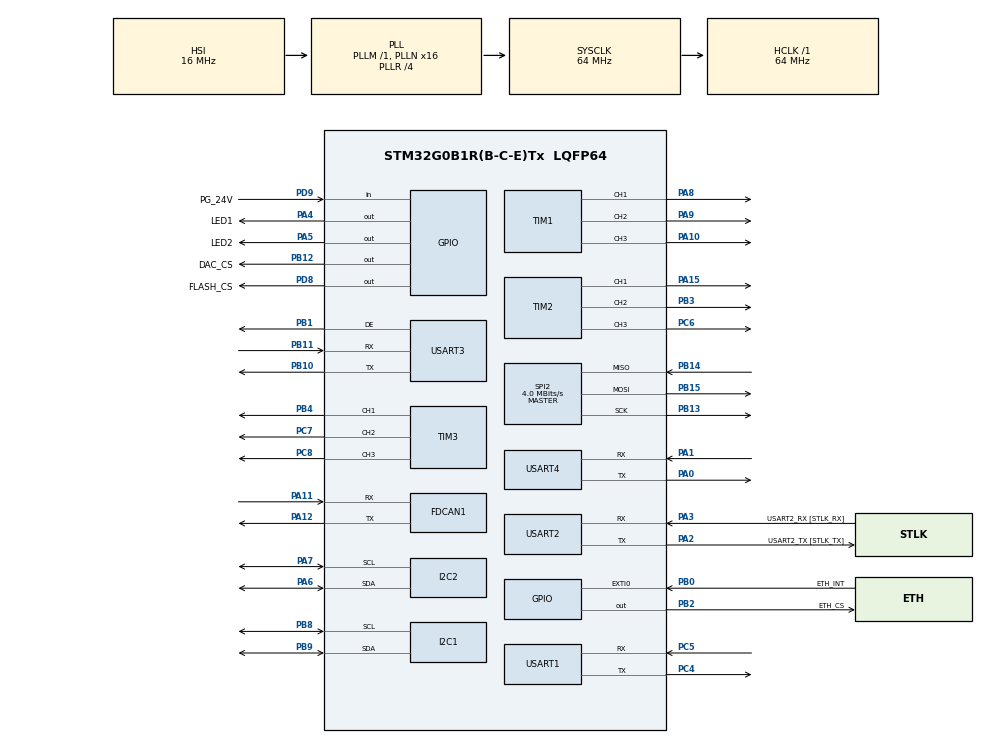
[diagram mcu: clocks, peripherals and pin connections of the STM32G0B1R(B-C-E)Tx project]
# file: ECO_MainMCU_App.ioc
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ADC1.AWD1HighThreshold=2500
ADC1.AWD1ITMode=ENABLE
ADC1.AWD1LowThreshold=2000
ADC1.Channel-0\#ChannelRegularConversion=ADC_CHANNEL_VREFINT
ADC1.Channel-1\#ChannelRegularConversion=ADC_CHANNEL_VBAT
ADC1.Channel-2\#ChannelRegularConversion=ADC_CHANNEL_TEMPSENSOR
ADC1.ClockPrescaler=ADC_CLOCK_SYNC_PCLK_DIV2
ADC1.DMAContinuousRequests=ENABLE
ADC1.DiscontinuousConvMode=DISABLE
ADC1.EOCSelection=ADC_EOC_SEQ_CONV
ADC1.EnableAnalogWatchDog1=true
ADC1.NbrOfConversion=3
ADC1.NbrOfConversionFlag=1
ADC1.OversamplingMode=ENABLE
ADC1.Rank-0\#ChannelRegularConversion=1
ADC1.Rank-1\#ChannelRegularConversion=2
ADC1.Rank-2\#ChannelRegularConversion=3
ADC1.Ratio=ADC_OVERSAMPLING_RATIO_16
ADC1.RightBitShift=ADC_RIGHTBITSHIFT_2
ADC1.SamplingTime-0\#ChannelRegularConversion=ADC_SAMPLINGTIME_COMMON_1
ADC1.SamplingTime-1\#ChannelRegularConversion=ADC_SAMPLINGTIME_COMMON_1
ADC1.SamplingTime-2\#ChannelRegularConversion=ADC_SAMPLINGTIME_COMMON_1
ADC1.SamplingTimeCommon1=ADC_SAMPLETIME_79CYCLES_5
ADC1.SamplingTimeCommon2=ADC_SAMPLETIME_79CYCLES_5
ADC1.SelectedChannel=ADC_CHANNEL_TEMPSENSOR|ADC_CHANNEL_VREFINT|ADC_CHANNEL_VBAT
ADC1.TriggerFrequencyMode=ADC_TRIGGER_FREQ_LOW
ADC1.TriggeredMode=ADC_TRIGGEREDMODE_SINGLE_TRIGGER
ADC1.WatchdogChannel=ADC_CHANNEL_VREFINT
ADC1.master=1
CRC.CRCLength=CRC_POLYLENGTH_16B
CRC.DefaultInitValueUse=DEFAULT_INIT_VALUE_DISABLE
CRC.DefaultPolynomialUse=DEFAULT_POLYNOMIAL_DISABLE
CRC.InputDataInversionMode=CRC_INPUTDATA_INVERSION_BYTE
CRC.OutputDataInversionMode=CRC_OUTPUTDATA_INVERSION_ENABLE
Dma.ADC1.0.Direction=DMA_PERIPH_TO_MEMORY
Dma.ADC1.0.EventEnable=DISABLE
Dma.ADC1.0.Instance=DMA1_Channel1
Dma.ADC1.0.MemDataAlignment=DMA_MDATAALIGN_HALFWORD
Dma.ADC1.0.MemInc=DMA_MINC_ENABLE
Dma.ADC1.0.Mode=DMA_CIRCULAR
Dma.ADC1.0.PeriphDataAlignment=DMA_PDATAALIGN_HALFWORD
Dma.ADC1.0.PeriphInc=DMA_PINC_DISABLE
Dma.ADC1.0.Polarity=HAL_DMAMUX_REQ_GEN_RISING
Dma.ADC1.0.Priority=DMA_PRIORITY_LOW
Dma.ADC1.0.RequestNumber=1
Dma.ADC1.0.SignalID=NONE
Dma.ADC1.0.SyncEnable=DISABLE
Dma.ADC1.0.SyncPolarity=HAL_DMAMUX_SYNC_NO_EVENT
Dma.ADC1.0.SyncRequestNumber=1
Dma.ADC1.0.SyncSignalID=NONE
Dma.Request0=ADC1
Dma.Request1=USART1_RX
Dma.Request2=USART1_TX
Dma.Request3=USART3_RX
Dma.Request4=USART4_RX
Dma.Request5=USART4_TX
Dma.USART1_RX.1.Direction=DMA_PERIPH_TO_MEMORY
Dma.USART1_RX.1.EventEnable=DISABLE
Dma.USART1_RX.1.Instance=DMA2_Channel1
Dma.USART1_RX.1.MemDataAlignment=DMA_MDATAALIGN_BYTE
Dma.USART1_RX.1.MemInc=DMA_MINC_ENABLE
Dma.USART1_RX.1.Mode=DMA_NORMAL
Dma.USART1_RX.1.PeriphDataAlignment=DMA_PDATAALIGN_BYTE
Dma.USART1_RX.1.PeriphInc=DMA_PINC_DISABLE
Dma.USART1_RX.1.Polarity=HAL_DMAMUX_REQ_GEN_RISING
Dma.USART1_RX.1.Priority=DMA_PRIORITY_LOW
Dma.USART1_RX.1.RequestNumber=1
Dma.USART1_RX.1.SignalID=NONE
Dma.USART1_RX.1.SyncEnable=DISABLE
Dma.USART1_RX.1.SyncPolarity=HAL_DMAMUX_SYNC_NO_EVENT
Dma.USART1_RX.1.SyncRequestNumber=1
Dma.USART1_RX.1.SyncSignalID=NONE
Dma.USART1_TX.2.Direction=DMA_MEMORY_TO_PERIPH
Dma.USART1_TX.2.EventEnable=DISABLE
Dma.USART1_TX.2.Instance=DMA2_Channel2
Dma.USART1_TX.2.MemDataAlignment=DMA_MDATAALIGN_BYTE
Dma.USART1_TX.2.MemInc=DMA_MINC_ENABLE
Dma.USART1_TX.2.Mode=DMA_NORMAL
Dma.USART1_TX.2.PeriphDataAlignment=DMA_PDATAALIGN_BYTE
Dma.USART1_TX.2.PeriphInc=DMA_PINC_DISABLE
Dma.USART1_TX.2.Polarity=HAL_DMAMUX_REQ_GEN_RISING
Dma.USART1_TX.2.Priority=DMA_PRIORITY_LOW
Dma.USART1_TX.2.RequestNumber=1
Dma.USART1_TX.2.SignalID=NONE
Dma.USART1_TX.2.SyncEnable=DISABLE
Dma.USART1_TX.2.SyncPolarity=HAL_DMAMUX_SYNC_NO_EVENT
Dma.USART1_TX.2.SyncRequestNumber=1
Dma.USART1_TX.2.SyncSignalID=NONE
Dma.USART3_RX.3.Direction=DMA_PERIPH_TO_MEMORY
Dma.USART3_RX.3.EventEnable=DISABLE
Dma.USART3_RX.3.Instance=DMA2_Channel3
Dma.USART3_RX.3.MemDataAlignment=DMA_MDATAALIGN_BYTE
Dma.USART3_RX.3.MemInc=DMA_MINC_ENABLE
Dma.USART3_RX.3.Mode=DMA_NORMAL
Dma.USART3_RX.3.PeriphDataAlignment=DMA_PDATAALIGN_BYTE
Dma.USART3_RX.3.PeriphInc=DMA_PINC_DISABLE
Dma.USART3_RX.3.Polarity=HAL_DMAMUX_REQ_GEN_RISING
Dma.USART3_RX.3.Priority=DMA_PRIORITY_LOW
Dma.USART3_RX.3.RequestNumber=1
Dma.USART3_RX.3.SignalID=NONE
Dma.USART3_RX.3.SyncEnable=DISABLE
Dma.USART3_RX.3.SyncPolarity=HAL_DMAMUX_SYNC_NO_EVENT
Dma.USART3_RX.3.SyncRequestNumber=1
Dma.USART3_RX.3.SyncSignalID=NONE
Dma.USART4_RX.4.Direction=DMA_PERIPH_TO_MEMORY
Dma.USART4_RX.4.EventEnable=DISABLE
Dma.USART4_RX.4.Instance=DMA2_Channel4
Dma.USART4_RX.4.MemDataAlignment=DMA_MDATAALIGN_BYTE
Dma.USART4_RX.4.MemInc=DMA_MINC_ENABLE
Dma.USART4_RX.4.Mode=DMA_NORMAL
Dma.USART4_RX.4.PeriphDataAlignment=DMA_PDATAALIGN_BYTE
Dma.USART4_RX.4.PeriphInc=DMA_PINC_DISABLE
Dma.USART4_RX.4.Polarity=HAL_DMAMUX_REQ_GEN_RISING
Dma.USART4_RX.4.Priority=DMA_PRIORITY_LOW
Dma.USART4_RX.4.RequestNumber=1
Dma.USART4_RX.4.SignalID=NONE
Dma.USART4_RX.4.SyncEnable=DISABLE
Dma.USART4_RX.4.SyncPolarity=HAL_DMAMUX_SYNC_NO_EVENT
Dma.USART4_RX.4.SyncRequestNumber=1
Dma.USART4_RX.4.SyncSignalID=NONE
Dma.USART4_TX.5.Direction=DMA_MEMORY_TO_PERIPH
Dma.USART4_TX.5.EventEnable=DISABLE
Dma.USART4_TX.5.Instance=DMA2_Channel5
Dma.USART4_TX.5.MemDataAlignment=DMA_MDATAALIGN_BYTE
Dma.USART4_TX.5.MemInc=DMA_MINC_ENABLE
Dma.USART4_TX.5.Mode=DMA_NORMAL
Dma.USART4_TX.5.PeriphDataAlignment=DMA_PDATAALIGN_BYTE
Dma.USART4_TX.5.PeriphInc=DMA_PINC_DISABLE
Dma.USART4_TX.5.Polarity=HAL_DMAMUX_REQ_GEN_RISING
Dma.USART4_TX.5.Priority=DMA_PRIORITY_LOW
Dma.USART4_TX.5.RequestNumber=1
Dma.USART4_TX.5.SignalID=NONE
Dma.USART4_TX.5.SyncEnable=DISABLE
Dma.USART4_TX.5.SyncPolarity=HAL_DMAMUX_SYNC_NO_EVENT
Dma.USART4_TX.5.SyncRequestNumber=1
Dma.USART4_TX.5.SyncSignalID=NONE
FDCAN1.CalculateBaudRateNominal=800000
FDCAN1.CalculateTimeBitNominal=1250
FDCAN1.CalculateTimeQuantumNominal=250.0
I2C1.Timing=0x10707DBC
I2C2.Timing=0x10707DBC
Mcu.Family=STM32G0
Mcu.Name=STM32G0B1R(B-C-E)Tx
Mcu.Package=LQFP64
NVIC.DMA1_Ch4_7_DMA2_Ch1_5_DMAMUX1_OVR_IRQn=true\:0\:0\:false\:false\:true\:false\:true\:true
NVIC.DMA1_Channel1_IRQn=true\:0\:0\:false\:false\:true\:false\:true\:true
NVIC.EXTI0_1_IRQn=true\:3\:0\:true\:false\:true\:true\:true\:true
NVIC.TIM17_FDCAN_IT1_IRQn=true\:3\:0\:false\:false\:true\:false\:true\:true
NVIC.TimeBase=TIM17_FDCAN_IT1_IRQn
NVIC.TimeBaseIP=TIM17
NVIC.USART1_IRQn=true\:3\:0\:true\:false\:true\:true\:true\:true
NVIC.USART2_LPUART2_IRQn=true\:3\:0\:true\:false\:true\:true\:true\:true
NVIC.USART3_4_5_6_LPUART1_IRQn=true\:3\:0\:true\:false\:true\:true\:true\:true
PA0.Mode=Asynchronous
PA0.Signal=USART4_TX
PA1.Mode=Asynchronous
PA1.Signal=USART4_RX
PA10.Signal=S_TIM1_CH3
PA11\ [PA9].Mode=FDCAN_Activate
PA11\ [PA9].Signal=FDCAN1_RX
PA12\ [PA10].Mode=FDCAN_Activate
PA12\ [PA10].Signal=FDCAN1_TX
PA13.GPIO_Label=TMS
PA13.Mode=Serial_Wire
PA13.Signal=SYS_SWDIO
PA14-BOOT0.GPIO_Label=TCK
PA14-BOOT0.Mode=Serial_Wire
PA14-BOOT0.Signal=SYS_SWCLK
PA15.Signal=S_TIM2_CH1_ETR
PA2.GPIO_Label=USART2_TX [STLK_TX]
PA2.Mode=Asynchronous
PA2.Signal=USART2_TX
PA3.GPIO_Label=USART2_RX [STLK_RX]
PA3.Mode=Asynchronous
PA3.Signal=USART2_RX
PA4.GPIO_Label=LED1
PA4.Signal=GPIO_Output
PA5.GPIO_Label=LED2
PA5.GPIO_Speed=GPIO_SPEED_FREQ_HIGH
PA5.Signal=GPIO_Output
PA6.Mode=I2C
PA6.Signal=I2C2_SDA
PA7.Mode=I2C
PA7.Signal=I2C2_SCL
PA8.Signal=S_TIM1_CH1
PA9.Signal=S_TIM1_CH2
PB0.GPIO_Label=ETH_INT
PB0.GPIO_ModeDefaultEXTI=GPIO_MODE_IT_FALLING
PB0.Signal=GPXTI0
PB1.Mode=Hardware Flow Control (RS485)
PB1.Signal=USART3_DE
PB10.Mode=Asynchronous
PB10.Signal=USART3_TX
PB11.Mode=Asynchronous
PB11.Signal=USART3_RX
PB12.GPIO_Label=DAC_CS
PB12.Signal=GPIO_Output
PB13.Mode=Full_Duplex_Master
PB13.Signal=SPI2_SCK
PB14.Mode=Full_Duplex_Master
PB14.Signal=SPI2_MISO
PB15.Mode=Full_Duplex_Master
PB15.Signal=SPI2_MOSI
PB2.GPIO_Label=ETH_CS
PB2.Signal=GPIO_Output
PB3.Signal=S_TIM2_CH2
PB4.Signal=S_TIM3_CH1
PB8.Mode=I2C
PB8.Signal=I2C1_SCL
PB9.Mode=I2C
PB9.Signal=I2C1_SDA
PC13.Mode=SYS_WakeUp1
PC13.Signal=SYS_WKUP2
PC14-OSC32_IN\ (PC14).Mode=LSE-External-Oscillator
PC14-OSC32_IN\ (PC14).Signal=RCC_OSC32_IN
PC15-OSC32_OUT\ (PC15).Mode=LSE-External-Oscillator
PC15-OSC32_OUT\ (PC15).Signal=RCC_OSC32_OUT
PC4.GPIO_PuPd=GPIO_NOPULL
PC4.Mode=Asynchronous
PC4.Signal=USART1_TX
PC5.GPIO_PuPd=GPIO_NOPULL
PC5.Mode=Asynchronous
PC5.Signal=USART1_RX
PC6.Signal=S_TIM2_CH3
PC7.Signal=S_TIM3_CH2
PC8.Signal=S_TIM3_CH3
PD8.GPIO_Label=FLASH_CS
PD8.Signal=GPIO_Output
PD9.GPIO_Label=PG_24V
PD9.Signal=GPIO_Input
PF0-OSC_IN\ (PF0).Mode=HSE-External-Oscillator
PF0-OSC_IN\ (PF0).Signal=RCC_OSC_IN
PF1-OSC_OUT\ (PF1).Mode=HSE-External-Oscillator
PF1-OSC_OUT\ (PF1).Signal=RCC_OSC_OUT
ProjectManager.HeapSize=0x200
ProjectManager.StackSize=0x800
ProjectManager.TargetToolchain=Makefile
RCC.ADCFreq_Value=64000000
RCC.AHBFreq_Value=64000000
RCC.CortexFreq_Value=64000000
RCC.EXTERNAL_CLOCK_VALUE=12288000
RCC.HCLKFreq_Value=64000000
RCC.HSE_VALUE=8000000
RCC.HSI48_VALUE=48000000
RCC.HSISYSCLKDivider=RCC_HSI_DIV2
RCC.HSI_VALUE=16000000
RCC.PLLN=16
RCC.PLLR=RCC_PLLR_DIV4
RCC.RTCClockSelection=RCC_RTCCLKSOURCE_LSE
RCC.SYSCLKFreq_VALUE=64000000
RCC.SYSCLKSource=RCC_SYSCLKSOURCE_PLLCLK
RCC.USBFreq_Value=48000000
RCC.VCOOutputFreq_Value=256000000
SH.S_TIM1_CH1.0=TIM1_CH1,PWM Generation1 CH1
SH.S_TIM1_CH2.0=TIM1_CH2,PWM Generation2 CH2
SH.S_TIM1_CH3.0=TIM1_CH3,Output Compare3 CH3
SH.S_TIM2_CH1_ETR.0=TIM2_CH1,PWM Generation1 CH1
SH.S_TIM2_CH2.0=TIM2_CH2,PWM Generation2 CH2
SH.S_TIM2_CH3.0=TIM2_CH3,PWM Generation3 CH3
SH.S_TIM3_CH1.0=TIM3_CH1,PWM Generation1 CH1
SH.S_TIM3_CH2.0=TIM3_CH2,PWM Generation2 CH2
SH.S_TIM3_CH3.0=TIM3_CH3,PWM Generation3 CH3
SPI2.BaudRatePrescaler=SPI_BAUDRATEPRESCALER_16
SPI2.CalculateBaudRate=4.0 MBits/s
SPI2.Direction=SPI_DIRECTION_2LINES
SPI2.Mode=SPI_MODE_MASTER
SPI2.VirtualType=VM_MASTER
TIM1.Channel-Output\ Compare3\ CH3=TIM_CHANNEL_3
TIM1.Channel-PWM\ Generation1\ CH1=TIM_CHANNEL_1
TIM1.Channel-PWM\ Generation2\ CH2=TIM_CHANNEL_2
TIM2.Channel-PWM\ Generation1\ CH1=TIM_CHANNEL_1
TIM2.Channel-PWM\ Generation2\ CH2=TIM_CHANNEL_2
TIM2.Channel-PWM\ Generation3\ CH3=TIM_CHANNEL_3
TIM3.Channel-PWM\ Generation1\ CH1=TIM_CHANNEL_1
TIM3.Channel-PWM\ Generation2\ CH2=TIM_CHANNEL_2
TIM3.Channel-PWM\ Generation3\ CH3=TIM_CHANNEL_3
USART1.SwapParam=ADVFEATURE_SWAP_ENABLE
USART1.VirtualMode-Asynchronous=VM_ASYNC
USART2.SwapParam=ADVFEATURE_SWAP_ENABLE
USART2.VirtualMode-Asynchronous=VM_ASYNC
USART3.VirtualMode-Asynchronous=VM_ASYNC
USART3.VirtualMode-Hardware\ Flow\ Control\ (RS485)=VM_ASYNC
USART4.VirtualMode-Asynchronous=VM_ASYNC
VP_ADC1_TempSens_Input.Mode=IN-TempSens
VP_ADC1_Vbat_Input.Mode=IN-Vbat
VP_ADC1_Vref_Input.Mode=IN-Vrefint
VP_CRC_VS_CRC.Mode=CRC_Activate
VP_RTC_VS_RTC_Activate.Mode=RTC_Enabled
VP_RTC_VS_RTC_Calendar.Mode=RTC_Calendar
VP_SYS_VS_tim17.Mode=TIM17
board=NUCLEO-G0B1RE

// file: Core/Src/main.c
/* USER CODE BEGIN Header */
/**
  ******************************************************************************
  * @file           : main.c
  * @brief          : Main program body
  ******************************************************************************
  * @attention
  *
  * Copyright (c) 2023 STMicroelectronics.
  * All rights reserved.
  *
  * This software is licensed under terms that can be found in the LICENSE file
  * in the root directory of this software component.
  * If no LICENSE file comes with this software, it is provided AS-IS.
  *
  ******************************************************************************
  */
/* USER CODE END Header */
#include "main.h"
#include "adc.h"
#include "crc.h"
#include "dma.h"
#include "fdcan.h"
#include "i2c.h"
#include "rtc.h"
#include "spi.h"
#include "tim.h"
#include "usart.h"
#include "gpio.h"

/* USER CODE BEGIN Includes */
#include "application.h"
/* USER CODE END Includes */

void SystemClock_Config(void);

int main(void)
{

  /* MCU Configuration--------------------------------------------------------*/

  /* Reset of all peripherals, Initializes the Flash interface and the Systick. */
  HAL_Init();

  /* Configure the system clock */
  SystemClock_Config();

  /* Initialize all configured peripherals */
  MX_GPIO_Init();
  MX_DMA_Init();
  MX_CRC_Init();
  MX_FDCAN1_Init();
  MX_I2C1_Init();
  MX_I2C2_Init();
  MX_RTC_Init();
  MX_SPI2_Init();
  MX_USART1_UART_Init();
  MX_USART2_UART_Init();
  MX_USART3_UART_Init();
  MX_USART4_UART_Init();
  MX_TIM1_Init();
  MX_TIM2_Init();
  MX_TIM3_Init();
  MX_ADC1_Init();
  /* USER CODE BEGIN 2 */
    Application_Init();
  /* USER CODE END 2 */

  /* Infinite loop */
  /* USER CODE BEGIN WHILE */
  Application_Run();
  while (1)
  {
    /* USER CODE END WHILE */

  }
}

void SystemClock_Config(void)
{
  RCC_OscInitTypeDef RCC_OscInitStruct = {0};
  RCC_ClkInitTypeDef RCC_ClkInitStruct = {0};

  /** Configure the main internal regulator output voltage
  */
  HAL_PWREx_ControlVoltageScaling(PWR_REGULATOR_VOLTAGE_SCALE1);

  /** Configure LSE Drive Capability
  */
  HAL_PWR_EnableBkUpAccess();
  __HAL_RCC_LSEDRIVE_CONFIG(RCC_LSEDRIVE_LOW);

  /** Initializes the RCC Oscillators according to the specified parameters
  * in the RCC_OscInitTypeDef structure.
  */
  RCC_OscInitStruct.OscillatorType = RCC_OSCILLATORTYPE_HSI|RCC_OSCILLATORTYPE_LSE;
  RCC_OscInitStruct.LSEState = RCC_LSE_ON;
  RCC_OscInitStruct.HSIState = RCC_HSI_ON;
  RCC_OscInitStruct.HSIDiv = RCC_HSI_DIV2;
  RCC_OscInitStruct.HSICalibrationValue = RCC_HSICALIBRATION_DEFAULT;
  RCC_OscInitStruct.PLL.PLLState = RCC_PLL_ON;
  RCC_OscInitStruct.PLL.PLLSource = RCC_PLLSOURCE_HSI;
  RCC_OscInitStruct.PLL.PLLM = RCC_PLLM_DIV1;
  RCC_OscInitStruct.PLL.PLLN = 16;
  RCC_OscInitStruct.PLL.PLLP = RCC_PLLP_DIV2;
  RCC_OscInitStruct.PLL.PLLQ = RCC_PLLQ_DIV2;
  RCC_OscInitStruct.PLL.PLLR = RCC_PLLR_DIV4;
  if (HAL_RCC_OscConfig(&RCC_OscInitStruct) != HAL_OK)
  {
    Error_Handler();
  }

  /** Initializes the CPU, AHB and APB buses clocks
  */
  RCC_ClkInitStruct.ClockType = RCC_CLOCKTYPE_HCLK|RCC_CLOCKTYPE_SYSCLK
                              |RCC_CLOCKTYPE_PCLK1;
  RCC_ClkInitStruct.SYSCLKSource = RCC_SYSCLKSOURCE_PLLCLK;
  RCC_ClkInitStruct.AHBCLKDivider = RCC_SYSCLK_DIV1;
  RCC_ClkInitStruct.APB1CLKDivider = RCC_HCLK_DIV1;

  if (HAL_RCC_ClockConfig(&RCC_ClkInitStruct, FLASH_LATENCY_2) != HAL_OK)
  {
    Error_Handler();
  }
}

void HAL_TIM_PeriodElapsedCallback(TIM_HandleTypeDef *htim)
{
  if (htim->Instance == TIM17) {
    HAL_IncTick();
  }
}

void Error_Handler(void)
{
  __disable_irq();
  while (1)
  {
  }
}
